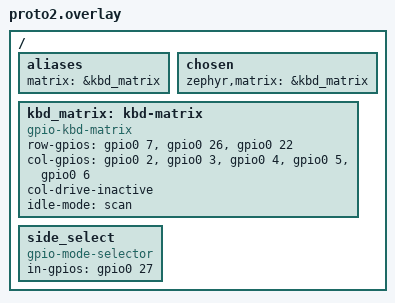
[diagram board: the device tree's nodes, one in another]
/* Device tree overlay for Proto2 keyboard matrix
 *
 * This board only supports the sparkfun_promicro_rp2040 board, which is mounted
 * directly onto the board, so we don't use the connector, but just directly
 * attach to the GPIOs.
 */

/ {
	aliases {
		matrix = &kbd_matrix;
	};

	chosen {
		zephyr,matrix = &kbd_matrix;
	};

	kbd_matrix: kbd-matrix {
		compatible = "gpio-kbd-matrix";
		row-gpios = <&gpio0 7 (GPIO_PULL_DOWN | GPIO_ACTIVE_HIGH)>,
			    <&gpio0 26 (GPIO_PULL_DOWN | GPIO_ACTIVE_HIGH)>,
			    <&gpio0 22 (GPIO_PULL_DOWN | GPIO_ACTIVE_HIGH)>;
		col-gpios = <&gpio0 2 GPIO_ACTIVE_HIGH>,
			    <&gpio0 3 GPIO_ACTIVE_HIGH>,
			    <&gpio0 4 GPIO_ACTIVE_HIGH>,
			    <&gpio0 5 GPIO_ACTIVE_HIGH>,
			    <&gpio0 6 GPIO_ACTIVE_HIGH>;
		col-drive-inactive;
		idle-mode = "scan";
	};

        side_select {
                compatible = "gpio-mode-selector";
                in-gpios = <&gpio0 27 (GPIO_PULL_UP | GPIO_ACTIVE_HIGH)>;
        };
};
